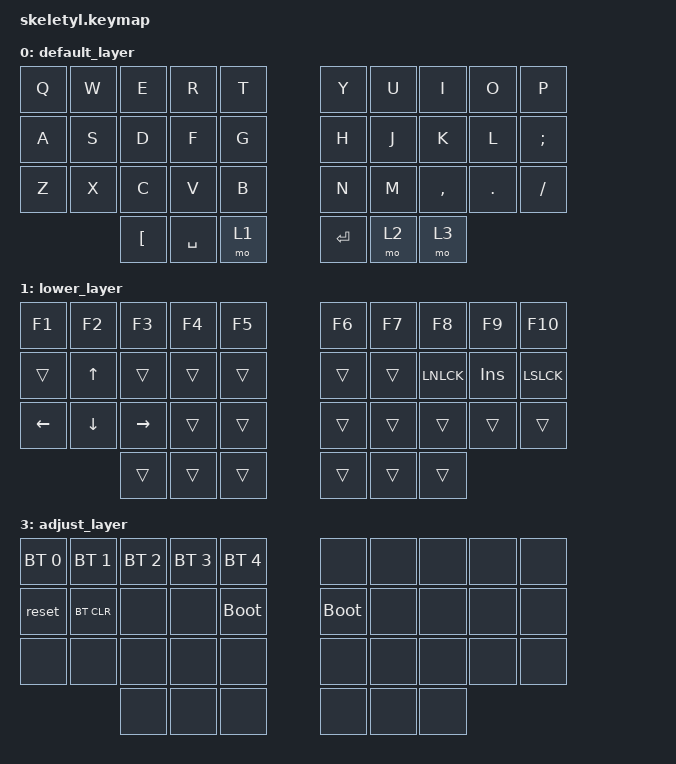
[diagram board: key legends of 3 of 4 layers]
#include <behaviors.dtsi>
#include <dt-bindings/zmk/keys.h>
#include <dt-bindings/zmk/bt.h>

#define DEFAULT 0
#define LWR 1
#define RSE 2
#define ADJ 3

/ {
    keymap {
        compatible = "zmk,keymap";

        default_layer {
            bindings = <
                &kp Q  &kp W  &kp E    &kp R     &kp T               &kp Y     &kp U  &kp I     &kp O   &kp P
                &kp A  &kp S  &kp D    &kp F     &kp G               &kp H     &kp J  &kp K     &kp L   &kp SEMI
                &kp Z  &kp X  &kp C    &kp V     &kp B               &kp N     &kp M  &kp COMMA &kp DOT &kp FSLH
                              &kp LBKT &kp SPACE &mo 1               &kp ENTER &mo 2  &mo 3
            >;
        };

        lower_layer {
            bindings = <
                &kp F1   &kp F2   &kp F3    &kp F4 &kp F5                &kp F6  &kp F7 &kp F8    &kp F9  &kp F10
                &trans   &kp UP   &trans    &trans &trans                &trans  &trans &kp LNLCK &kp INS &kp LSLCK
                &kp LEFT &kp DOWN &kp RIGHT &trans &trans                &trans  &trans &trans    &trans  &trans
                                  &trans    &trans &trans                &trans  &trans &trans
            >;
        };

        raise_layer {
            bindings = <
                &trans &trans &trans &trans &trans                &trans &kp KP_N7 &kp KP_N8 &kp KP_N9 &trans
                &trans &trans &trans &trans &trans                &trans &kp KP_N4 &kp KP_N5 &kp KP_N6 &trans
                &trans &trans &trans &trans &trans                &trans &kp KP_N1 &kp KP_N2 &kp KP_N3 &trans
                              &trans &trans &trans                &trans &trans
            >;
        };

        adjust_layer {
            bindings = <
                &bt BT_SEL 0  &bt BT_SEL 1  &bt BT_SEL 2  &bt BT_SEL 3  &bt BT_SEL 4                  &none        &none  &none  &none  &none
                &reset        &bt BT_CLR    &none         &none         &bootloader                   &bootloader  &none  &none  &none  &none
                &none         &none         &none         &none         &none                         &none        &none  &none  &none  &none
                                            &none         &none         &none                         &none        &none  &none
            >;
        };
    };
};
